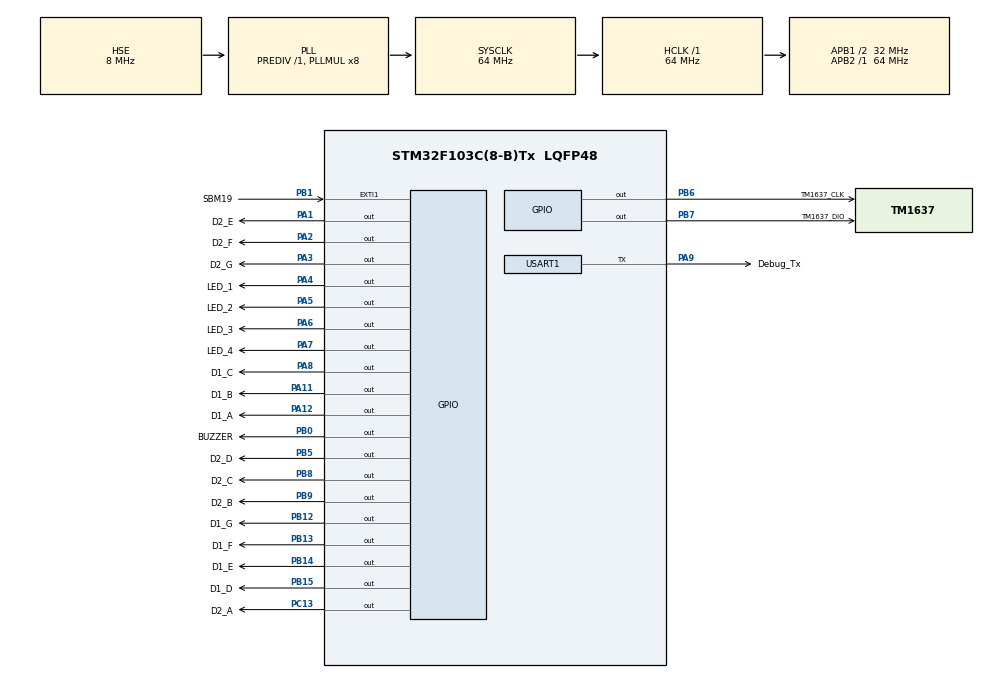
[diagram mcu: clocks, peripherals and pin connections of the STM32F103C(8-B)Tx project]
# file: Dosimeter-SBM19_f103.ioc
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Mcu.Family=STM32F1
Mcu.Name=STM32F103C(8-B)Tx
Mcu.Package=LQFP48
NVIC.EXTI1_IRQn=true\:0\:0\:false\:false\:true\:true\:true\:true
NVIC.PriorityGroup=NVIC_PRIORITYGROUP_4
NVIC.TIM3_IRQn=true\:0\:0\:false\:false\:true\:true\:true\:true
PA1.GPIO_Label=D2_E
PA1.Signal=GPIO_Output
PA11.GPIO_Label=D1_B
PA11.Signal=GPIO_Output
PA12.GPIO_Label=D1_A
PA12.Signal=GPIO_Output
PA13.Mode=Serial_Wire
PA13.Signal=SYS_JTMS-SWDIO
PA14.Mode=Serial_Wire
PA14.Signal=SYS_JTCK-SWCLK
PA2.GPIO_Label=D2_F
PA2.Signal=GPIO_Output
PA3.GPIO_Label=D2_G
PA3.Signal=GPIO_Output
PA4.GPIO_Label=LED_1
PA4.PinState=GPIO_PIN_SET
PA4.Signal=GPIO_Output
PA5.GPIO_Label=LED_2
PA5.PinState=GPIO_PIN_SET
PA5.Signal=GPIO_Output
PA6.GPIO_Label=LED_3
PA6.PinState=GPIO_PIN_SET
PA6.Signal=GPIO_Output
PA7.GPIO_Label=LED_4
PA7.PinState=GPIO_PIN_SET
PA7.Signal=GPIO_Output
PA8.GPIO_Label=D1_C
PA8.Signal=GPIO_Output
PA9.GPIO_Label=Debug_Tx
PA9.Mode=Half_duplex(single_wire_mode)
PA9.Signal=USART1_TX
PB0.GPIO_Label=BUZZER
PB0.Signal=GPIO_Output
PB1.GPIO_Label=SBM19
PB1.GPIO_ModeDefaultEXTI=GPIO_MODE_IT_FALLING
PB1.GPIO_PuPd=GPIO_PULLUP
PB1.Signal=GPXTI1
PB12.GPIO_Label=D1_G
PB12.Signal=GPIO_Output
PB13.GPIO_Label=D1_F
PB13.Signal=GPIO_Output
PB14.GPIO_Label=D1_E
PB14.Signal=GPIO_Output
PB15.GPIO_Label=D1_D
PB15.Signal=GPIO_Output
PB5.GPIO_Label=D2_D
PB5.Signal=GPIO_Output
PB6.GPIO_Label=TM1637_CLK
PB6.Signal=GPIO_Output
PB7.GPIO_Label=TM1637_DIO
PB7.Signal=GPIO_Output
PB8.GPIO_Label=D2_C
PB8.Signal=GPIO_Output
PB9.GPIO_Label=D2_B
PB9.Signal=GPIO_Output
PC13-TAMPER-RTC.GPIO_Label=D2_A
PC13-TAMPER-RTC.Signal=GPIO_Output
PD0-OSC_IN.Mode=HSE-External-Oscillator
PD0-OSC_IN.Signal=RCC_OSC_IN
PD1-OSC_OUT.Mode=HSE-External-Oscillator
PD1-OSC_OUT.Signal=RCC_OSC_OUT
ProjectManager.HeapSize=0x200
ProjectManager.StackSize=0x400
ProjectManager.TargetToolchain=STM32CubeIDE
RCC.AHBFreq_Value=64000000
RCC.APB1CLKDivider=RCC_HCLK_DIV2
RCC.APB1Freq_Value=32000000
RCC.APB1TimFreq_Value=64000000
RCC.APB2Freq_Value=64000000
RCC.APB2TimFreq_Value=64000000
RCC.HCLKFreq_Value=64000000
RCC.PLLMUL=RCC_PLL_MUL8
RCC.PLLSourceVirtual=RCC_PLLSOURCE_HSE
RCC.SYSCLKFreq_VALUE=64000000
RCC.SYSCLKSource=RCC_SYSCLKSOURCE_PLLCLK
RCC.USBFreq_Value=64000000
TIM3.Period=60000-1
TIM3.Prescaler=64000-1
TIM4.Period=10000-1
TIM4.Prescaler=64000-1
USART1.BaudRate=62500
USART1.Mode=MODE_TX
USART1.VirtualMode=VM_ASYNC
VP_TIM3_VS_ClockSourceINT.Mode=Internal
VP_TIM4_VS_ClockSourceINT.Mode=Internal
board=custom

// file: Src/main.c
/* USER CODE BEGIN Header */
/**
  ******************************************************************************
  * @file           : main.c
  * @brief          : Main program body
  ******************************************************************************
  * @attention
  *
  * <h2><center>&copy; Copyright (c) 2020 STMicroelectronics.
  * All rights reserved.</center></h2>
  *
  * This software component is licensed by ST under BSD 3-Clause license,
  * the "License"; You may not use this file except in compliance with the
  * License. You may obtain a copy of the License at:
  *                        opensource.org/licenses/BSD-3-Clause
  *
  ******************************************************************************
  */
/* USER CODE END Header */
#include "main.h"
#include "tim.h"
#include "usart.h"
#include "gpio.h"

/* USER CODE BEGIN Includes */

	#include "dosimeter_sbm19_sm.h"

/* USER CODE END Includes */

void SystemClock_Config(void);

int main(void)
{

  /* MCU Configuration--------------------------------------------------------*/

  /* Reset of all peripherals, Initializes the Flash interface and the Systick. */
  HAL_Init();

  /* Configure the system clock */
  SystemClock_Config();

  /* Initialize all configured peripherals */
  MX_GPIO_Init();
  MX_TIM4_Init();
  MX_USART1_UART_Init();
  MX_TIM3_Init();
  /* USER CODE BEGIN 2 */

	Dozimeter_Init();

  /* USER CODE END 2 */

  /* Infinite loop */
  /* USER CODE BEGIN WHILE */
  while (1)
  {
	Dozimeter_Main();

    /* USER CODE END WHILE */

  }
}

void SystemClock_Config(void)
{
  RCC_OscInitTypeDef RCC_OscInitStruct = {0};
  RCC_ClkInitTypeDef RCC_ClkInitStruct = {0};

  /** Initializes the RCC Oscillators according to the specified parameters
  * in the RCC_OscInitTypeDef structure.
  */
  RCC_OscInitStruct.OscillatorType = RCC_OSCILLATORTYPE_HSE;
  RCC_OscInitStruct.HSEState = RCC_HSE_ON;
  RCC_OscInitStruct.HSEPredivValue = RCC_HSE_PREDIV_DIV1;
  RCC_OscInitStruct.HSIState = RCC_HSI_ON;
  RCC_OscInitStruct.PLL.PLLState = RCC_PLL_ON;
  RCC_OscInitStruct.PLL.PLLSource = RCC_PLLSOURCE_HSE;
  RCC_OscInitStruct.PLL.PLLMUL = RCC_PLL_MUL8;
  if (HAL_RCC_OscConfig(&RCC_OscInitStruct) != HAL_OK)
  {
    Error_Handler();
  }

  /** Initializes the CPU, AHB and APB buses clocks
  */
  RCC_ClkInitStruct.ClockType = RCC_CLOCKTYPE_HCLK|RCC_CLOCKTYPE_SYSCLK
                              |RCC_CLOCKTYPE_PCLK1|RCC_CLOCKTYPE_PCLK2;
  RCC_ClkInitStruct.SYSCLKSource = RCC_SYSCLKSOURCE_PLLCLK;
  RCC_ClkInitStruct.AHBCLKDivider = RCC_SYSCLK_DIV1;
  RCC_ClkInitStruct.APB1CLKDivider = RCC_HCLK_DIV2;
  RCC_ClkInitStruct.APB2CLKDivider = RCC_HCLK_DIV1;

  if (HAL_RCC_ClockConfig(&RCC_ClkInitStruct, FLASH_LATENCY_2) != HAL_OK)
  {
    Error_Handler();
  }
}

void Error_Handler(void)
{
}
